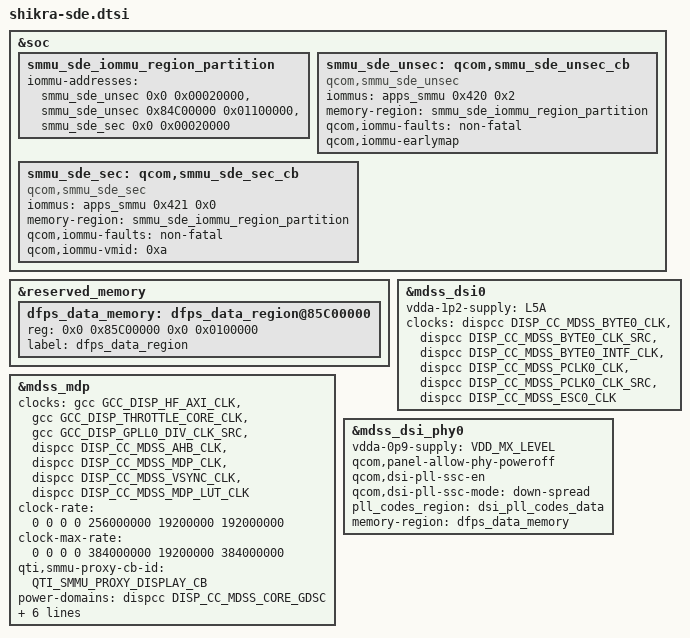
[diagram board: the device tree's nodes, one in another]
// SPDX-License-Identifier: BSD-3-Clause
/*
 * Copyright (c) Qualcomm Technologies, Inc. and/or its subsidiaries.
 */

#include <dt-bindings/clock/qcom,shikra-gcc.h>
#include <dt-bindings/clock/qcom,shikra-dispcc.h>
#include <dt-bindings/interconnect/qcom,shikra.h>
#include <dt-bindings/arm/msm/qti-smmu-proxy-dt-ids.h>

#include "shikra-sde-common.dtsi"

&soc {
	smmu_sde_iommu_region_partition: smmu_sde_iommu_region_partition {
		iommu-addresses = <&smmu_sde_unsec 0x0 0x00020000>,
				<&smmu_sde_unsec 0x84C00000 0x01100000>,
				<&smmu_sde_sec 0x0 0x00020000>;
	};

	smmu_sde_unsec: qcom,smmu_sde_unsec_cb {
		compatible = "qcom,smmu_sde_unsec";
		iommus = <&apps_smmu 0x420 0x2>;
		memory-region = <&smmu_sde_iommu_region_partition>;
		qcom,iommu-faults = "non-fatal";
		qcom,iommu-earlymap; /* for cont-splash */
	};

	smmu_sde_sec: qcom,smmu_sde_sec_cb {
		compatible = "qcom,smmu_sde_sec";
		iommus = <&apps_smmu 0x421 0x0>;
		memory-region = <&smmu_sde_iommu_region_partition>;
		qcom,iommu-faults = "non-fatal";
		qcom,iommu-vmid = <0xa>;
	};
};

&reserved_memory {
	dfps_data_memory: dfps_data_region@85C00000 {
		reg = <0x0 0x85C00000 0x0 0x0100000>;
		label = "dfps_data_region";
	};
};

&mdss_mdp {
		clocks =
			<&gcc GCC_DISP_HF_AXI_CLK>,
			<&gcc GCC_DISP_THROTTLE_CORE_CLK>,
			<&gcc GCC_DISP_GPLL0_DIV_CLK_SRC>,
			<&dispcc DISP_CC_MDSS_AHB_CLK>,
			<&dispcc DISP_CC_MDSS_MDP_CLK>,
			<&dispcc DISP_CC_MDSS_VSYNC_CLK>,
			<&dispcc DISP_CC_MDSS_MDP_LUT_CLK>;
		clock-names = "gcc_bus", "throttle_clk", "div_clk",
				"iface_clk", "core_clk", "vsync_clk",
				"lut_clk";
		clock-rate = <0 0 0 0 256000000 19200000 192000000>;
		clock-max-rate = <0 0 0 0 384000000 19200000 384000000>;

		qti,smmu-proxy-cb-id = <QTI_SMMU_PROXY_DISPLAY_CB>;

		power-domains = <&dispcc DISP_CC_MDSS_CORE_GDSC>;

		interconnects = <&mmrt_virt MASTER_MDP_PORT0 &mem_noc SLAVE_LLCC>,
				<&mc_virt MASTER_LLCC &mc_virt SLAVE_EBI_CH0>,
				<&mem_noc MASTER_AMPSS_M0 &config_noc SLAVE_DISPLAY_CFG>;
		interconnect-names = "qcom,sde-data-bus0", "qcom,sde-ebi-bus",
					"qcom,sde-reg-bus";

		qcom,sde-ib-bw-vote = <2400000 0 1600000>;
};

&mdss_dsi0 {
	vdda-1p2-supply = <&L5A>;
		clocks =
			<&dispcc DISP_CC_MDSS_BYTE0_CLK>,
			<&dispcc DISP_CC_MDSS_BYTE0_CLK_SRC>,
			<&dispcc DISP_CC_MDSS_BYTE0_INTF_CLK>,
			<&dispcc DISP_CC_MDSS_PCLK0_CLK>,
			<&dispcc DISP_CC_MDSS_PCLK0_CLK_SRC>,
			<&dispcc DISP_CC_MDSS_ESC0_CLK>;
		clock-names = "byte_clk", "byte_clk_rcg", "byte_intf_clk",
				"pixel_clk", "pixel_clk_rcg",
				"esc_clk";
};

&mdss_dsi_phy0 {
	vdda-0p9-supply = <&VDD_MX_LEVEL>;
	qcom,panel-allow-phy-poweroff;
	qcom,dsi-pll-ssc-en;
	qcom,dsi-pll-ssc-mode = "down-spread";
	pll_codes_region = <&dsi_pll_codes_data>;
	memory-region = <&dfps_data_memory>;
};
